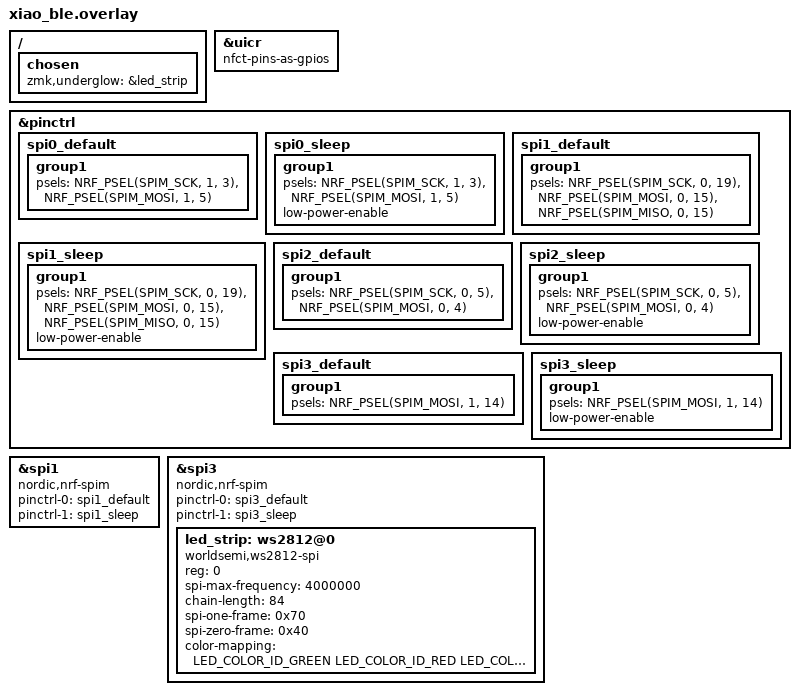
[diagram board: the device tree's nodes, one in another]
/*
 * XIAO BLE Board Configuration
 * Sets up all SPI buses and RGB underglow for the XIAO nRF52840
 */

/* Enable NFC pins as GPIO (required for some pins on XIAO) */
&uicr {
    nfct-pins-as-gpios;
};

/* 
 * SPI0 - Shift Register (74HC595)
 * SCK: P1.03, MOSI: P1.05, CS: P1.13 (defined in dtsi)
 */
&pinctrl {
    spi0_default: spi0_default {
        group1 {
            psels = <NRF_PSEL(SPIM_SCK, 1, 3)>,
                    <NRF_PSEL(SPIM_MOSI, 1, 5)>;
        };
    };
    spi0_sleep: spi0_sleep {
        group1 {
            psels = <NRF_PSEL(SPIM_SCK, 1, 3)>,
                    <NRF_PSEL(SPIM_MOSI, 1, 5)>;
            low-power-enable;
        };
    };
};

/*
 * SPI1 - PMW3610 Trackball
 * SCK: P0.19, MOSI/MISO: P0.15, CS: P0.02, IRQ: P0.29
 */
&pinctrl {
    spi1_default: spi1_default {
        group1 {
            psels = <NRF_PSEL(SPIM_SCK, 0, 19)>,
                    <NRF_PSEL(SPIM_MOSI, 0, 15)>,
                    <NRF_PSEL(SPIM_MISO, 0, 15)>;
        };
    };
    spi1_sleep: spi1_sleep {
        group1 {
            psels = <NRF_PSEL(SPIM_SCK, 0, 19)>,
                    <NRF_PSEL(SPIM_MOSI, 0, 15)>,
                    <NRF_PSEL(SPIM_MISO, 0, 15)>;
            low-power-enable;
        };
    };
};

&spi1 {
    status = "okay";
    compatible = "nordic,nrf-spim";
    pinctrl-0 = <&spi1_default>;
    pinctrl-1 = <&spi1_sleep>;
    pinctrl-names = "default", "sleep";
};

/*
 * SPI2 - Nice!View Display
 * SCK: P0.05, MOSI: P0.04, CS: P0.03
 */
&pinctrl {
    spi2_default: spi2_default {
        group1 {
            psels = <NRF_PSEL(SPIM_SCK, 0, 5)>,
                    <NRF_PSEL(SPIM_MOSI, 0, 4)>;
        };
    };
    spi2_sleep: spi2_sleep {
        group1 {
            psels = <NRF_PSEL(SPIM_SCK, 0, 5)>,
                    <NRF_PSEL(SPIM_MOSI, 0, 4)>;
            low-power-enable;
        };
    };
};

/*
 * SPI3 - WS2812 RGB LEDs
 * Data: P1.14
 */
#include <dt-bindings/led/led.h>

&pinctrl {
    spi3_default: spi3_default {
        group1 {
            psels = <NRF_PSEL(SPIM_MOSI, 1, 14)>;
        };
    };
    spi3_sleep: spi3_sleep {
        group1 {
            psels = <NRF_PSEL(SPIM_MOSI, 1, 14)>;
            low-power-enable;
        };
    };
};

&spi3 {
    compatible = "nordic,nrf-spim";
    status = "okay";
    pinctrl-0 = <&spi3_default>;
    pinctrl-1 = <&spi3_sleep>;
    pinctrl-names = "default", "sleep";

    led_strip: ws2812@0 {
        compatible = "worldsemi,ws2812-spi";
        reg = <0>;
        spi-max-frequency = <4000000>;
        
        /* Adjust chain-length to match your LED count */
        chain-length = <84>;
        spi-one-frame = <0x70>;
        spi-zero-frame = <0x40>;
        color-mapping = <LED_COLOR_ID_GREEN LED_COLOR_ID_RED LED_COLOR_ID_BLUE>;
    };
};

/ {
    chosen {
        zmk,underglow = &led_strip;
    };
};
